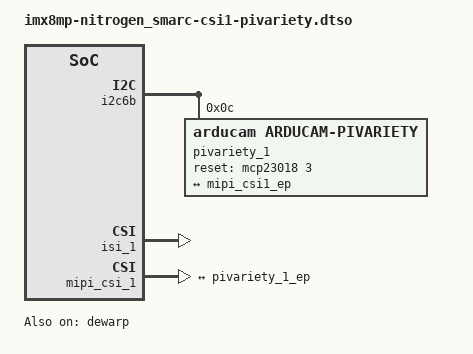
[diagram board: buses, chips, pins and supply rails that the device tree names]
// SPDX-License-Identifier: (GPL-2.0+ OR MIT)
/*
 * Copyright 2026 Ezurio LLC
 */

/dts-v1/;
/plugin/;

#include <dt-bindings/gpio/gpio.h>
#include "imx8mp-pinfunc.h"

&dewarp {
	status = "okay";
};

&i2c6b {
	#address-cells = <1>;
	#size-cells = <0>;

	pivariety_1: camera@c {
		compatible = "arducam,arducam-pivariety";
		reg = <0x0c>;
		clocks = <&csi_mclk>;
		clock-names = "xclk";
		reset-gpios = <&mcp23018 3 GPIO_ACTIVE_HIGH>;
		status = "okay";

		port {
			pivariety_1_ep: endpoint {
				remote-endpoint = <&mipi_csi1_ep>;
				clock-lanes = <0>;
				data-lanes = <1 2 3 4>;
			};
		};
	};
};

&isi_1 {
	status = "okay";

	cap_device {
		status = "okay";
	};
};

&isp_1 {
	status = "disabled";
};

&mipi_csi_1 {
	#address-cells = <1>;
	#size-cells = <0>;
	status = "okay";

	port@1 {
		reg = <1>;
		mipi_csi1_ep: endpoint {
			remote-endpoint = <&pivariety_1_ep>;
			data-lanes = <4>;
			csis-hs-settle = <30>;
			csis-clk-settle = <2>;
			csis-wclk;
		};
	};
};
